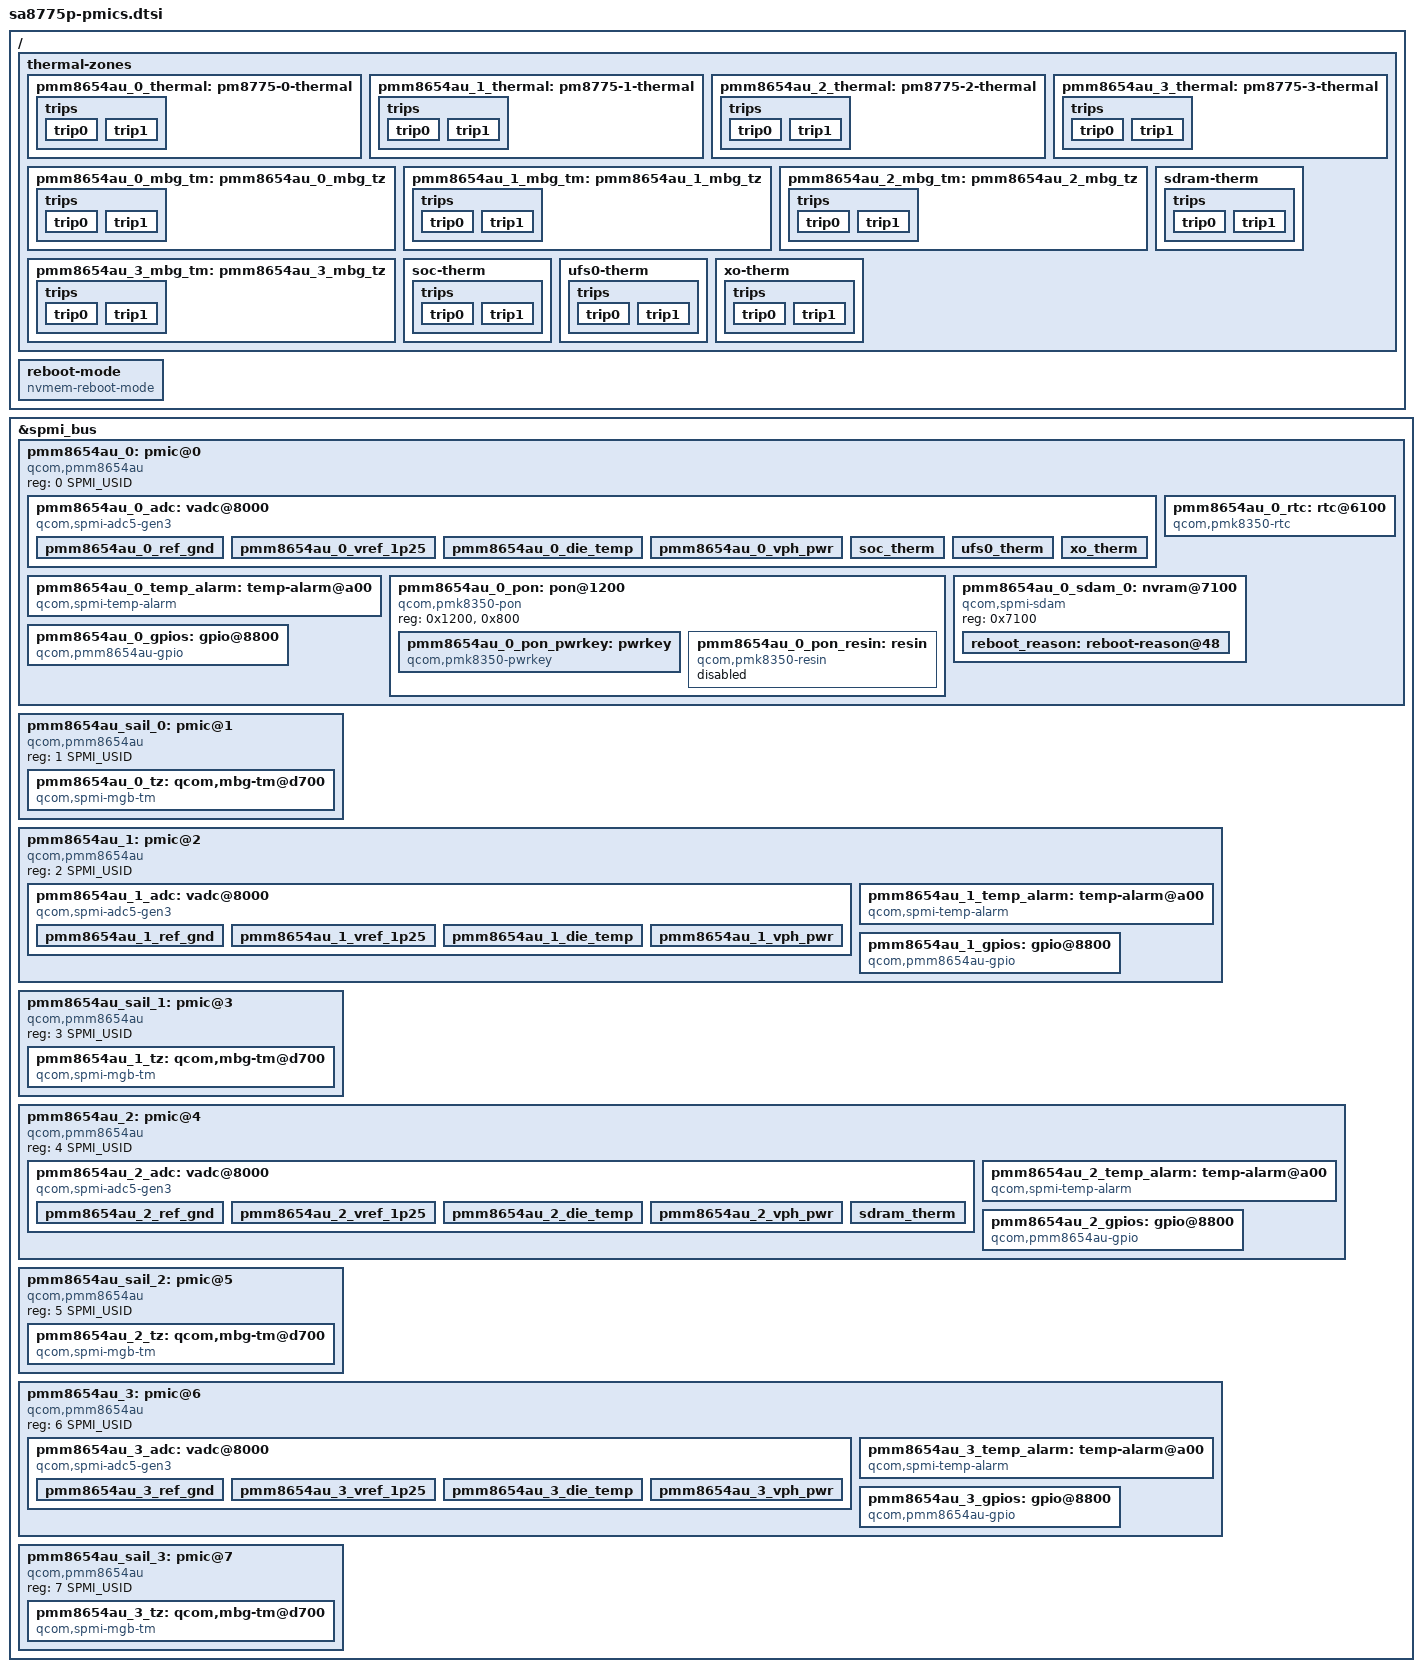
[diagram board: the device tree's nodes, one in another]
// SPDX-License-Identifier: BSD-3-Clause
/*
 * Copyright (c) 2023, Linaro Limited
 * Copyright (c) 2024, Qualcomm Innovation Center, Inc. All rights reserved.
 */

#include <dt-bindings/iio/qcom,spmi-adc5-gen3-pm8775.h>
#include <dt-bindings/input/input.h>
#include <dt-bindings/spmi/spmi.h>

/ {
	thermal-zones {
		pmm8654au_0_thermal: pm8775-0-thermal {
			polling-delay-passive = <100>;
			polling-delay = <0>;
			thermal-sensors = <&pmm8654au_0_temp_alarm>;

			trips {
				trip0 {
					temperature = <105000>;
					hysteresis = <0>;
					type = "passive";
				};

				trip1 {
					temperature = <125000>;
					hysteresis = <0>;
					type = "critical";
				};
			};
		};

		pmm8654au_1_thermal: pm8775-1-thermal {
			polling-delay-passive = <100>;
			polling-delay = <0>;
			thermal-sensors = <&pmm8654au_1_temp_alarm>;

			trips {
				trip0 {
					temperature = <105000>;
					hysteresis = <0>;
					type = "passive";
				};

				trip1 {
					temperature = <125000>;
					hysteresis = <0>;
					type = "critical";
				};
			};
		};

		pmm8654au_2_thermal: pm8775-2-thermal {
			polling-delay-passive = <100>;
			polling-delay = <0>;
			thermal-sensors = <&pmm8654au_2_temp_alarm>;

			trips {
				trip0 {
					temperature = <105000>;
					hysteresis = <0>;
					type = "passive";
				};

				trip1 {
					temperature = <125000>;
					hysteresis = <0>;
					type = "critical";
				};
			};
		};

		pmm8654au_3_thermal: pm8775-3-thermal {
			polling-delay-passive = <100>;
			polling-delay = <0>;
			thermal-sensors = <&pmm8654au_3_temp_alarm>;

			trips {
				trip0 {
					temperature = <105000>;
					hysteresis = <0>;
					type = "passive";
				};

				trip1 {
					temperature = <125000>;
					hysteresis = <0>;
					type = "critical";
				};
			};
		};

		pmm8654au_0_mbg_tm: pmm8654au_0_mbg_tz {
			polling-delay-passive = <100>;
			polling-delay = <0>;
			thermal-sensors = <&pmm8654au_0_tz>;

			trips {
				trip0 {
					temperature = <115000>;
					hysteresis = <5000>;
					type = "passive";
				};

				trip1 {
					temperature = <135000>;
					hysteresis = <5000>;
					type = "passive";
				};
			};
		};

		pmm8654au_1_mbg_tm: pmm8654au_1_mbg_tz {
			polling-delay-passive = <100>;
			polling-delay = <0>;
			thermal-sensors = <&pmm8654au_1_tz>;

			trips {
				trip0 {
					temperature = <115000>;
					hysteresis = <5000>;
					type = "passive";
				};

				trip1 {
					temperature = <135000>;
					hysteresis = <5000>;
					type = "passive";
				};
			};
		};

		pmm8654au_2_mbg_tm: pmm8654au_2_mbg_tz {
			polling-delay-passive = <100>;
			polling-delay = <0>;
			thermal-sensors = <&pmm8654au_2_tz>;

			trips {
				trip0 {
					temperature = <115000>;
					hysteresis = <5000>;
					type = "passive";
				};

				trip1 {
					temperature = <135000>;
					hysteresis = <5000>;
					type = "passive";
				};
			};
		};

		pmm8654au_3_mbg_tm: pmm8654au_3_mbg_tz {
			polling-delay-passive = <100>;
			polling-delay = <0>;
			thermal-sensors = <&pmm8654au_3_tz>;

			trips {
				trip0 {
					temperature = <115000>;
					hysteresis = <5000>;
					type = "passive";
				};

				trip1 {
					temperature = <135000>;
					hysteresis = <5000>;
					type = "passive";
				};

			};
		};

		sdram-therm {
			polling-delay-passive = <0>;
			polling-delay = <0>;
			thermal-sensors = <&pmm8654au_2_adc PM8775_3_ADC5_GEN3_AMUX6_THM_100K_PU>;
			trips {
				trip0 {
					temperature = <125000>;
					hysteresis = <1000>;
					type = "passive";
				};

				trip1 {
					temperature = <125000>;
					hysteresis = <1000>;
					type = "passive";
				};
			};
		};

		soc-therm {
			polling-delay-passive = <0>;
			polling-delay = <0>;
			thermal-sensors = <&pmm8654au_0_adc PM8775_1_ADC5_GEN3_AMUX6_THM_100K_PU>;
			trips {
				trip0 {
					temperature = <125000>;
					hysteresis = <1000>;
					type = "passive";
				};

				trip1 {
					temperature = <125000>;
					hysteresis = <1000>;
					type = "passive";
				};
			};
		};

		ufs0-therm {
			polling-delay-passive = <0>;
			polling-delay = <0>;
			thermal-sensors = <&pmm8654au_0_adc PM8775_1_ADC5_GEN3_AMUX5_THM_100K_PU>;
			trips {
				trip0 {
					temperature = <125000>;
					hysteresis = <1000>;
					type = "passive";
				};

				trip1 {
					temperature = <125000>;
					hysteresis = <1000>;
					type = "passive";
				};
			};
		};

		xo-therm {
			polling-delay-passive = <0>;
			polling-delay = <0>;
			thermal-sensors = <&pmm8654au_0_adc PM8775_1_ADC5_GEN3_AMUX1_THM_100K_PU>;
			trips {
				trip0 {
					temperature = <125000>;
					hysteresis = <1000>;
					type = "passive";
				};

				trip1 {
					temperature = <125000>;
					hysteresis = <1000>;
					type = "passive";
				};
			};
		};
	};

	reboot-mode {
		compatible = "nvmem-reboot-mode";
		nvmem-cells = <&reboot_reason>;
		nvmem-cell-names = "reboot-mode";
		mode-recovery = <0x01>;
		mode-bootloader = <0x02>;
	};
};

&spmi_bus {
	pmm8654au_0: pmic@0 {
		compatible = "qcom,pmm8654au", "qcom,spmi-pmic";
		reg = <0 SPMI_USID>;
		#address-cells = <1>;
		#size-cells = <0>;

		pmm8654au_0_adc: vadc@8000 {
			compatible = "qcom,spmi-adc5-gen3";
			reg = <0x8000>;
			reg-names = "adc5-gen3-base";
			#address-cells = <1>;
			#size-cells = <0>;
			interrupts-extended = <&spmi_bus 0x0 0x80 0x1 IRQ_TYPE_EDGE_RISING>;
			interrupt-names = "adc-sdam0";
			#io-channel-cells = <1>;
			#thermal-sensor-cells = <1>;

			pmm8654au_0_ref_gnd {
				reg = <PM8775_1_ADC5_GEN3_OFFSET_REF>;
				label = "pm8775_1_ref_gnd";
				qcom,pre-scaling = <1 1>;
			};

			pmm8654au_0_vref_1p25 {
				reg = <PM8775_1_ADC5_GEN3_1P25VREF>;
				label = "pm8775_1_vref_1p25";
				qcom,pre-scaling = <1 1>;
			};

			pmm8654au_0_die_temp {
				reg = <PM8775_1_ADC5_GEN3_DIE_TEMP>;
				label = "pm8775_1_die_temp";
				qcom,pre-scaling = <1 1>;
			};

			pmm8654au_0_vph_pwr {
				reg = <PM8775_1_ADC5_GEN3_VPH_PWR>;
				label = "pm8775_1_vph_pwr";
				qcom,pre-scaling = <1 3>;
			};

			soc_therm {
				reg = <PM8775_1_ADC5_GEN3_AMUX6_THM_100K_PU>;
				label = "pmm8654au_0_soc_therm";
				qcom,ratiometric;
				qcom,hw-settle-time = <200>;
				qcom,adc-tm;
				qcom,pre-scaling = <1 1>;
			};

			ufs0_therm {
				reg = <PM8775_1_ADC5_GEN3_AMUX5_THM_100K_PU>;
				label = "pmm8654au_0_ufs0_therm";
				qcom,ratiometric;
				qcom,hw-settle-time = <200>;
				qcom,adc-tm;
				qcom,pre-scaling = <1 1>;
			};

			xo_therm {
				reg = <PM8775_1_ADC5_GEN3_AMUX1_THM_100K_PU>;
				label = "pmm8654au_0_xo_therm";
				qcom,ratiometric;
				qcom,hw-settle-time = <700>;
				qcom,adc-tm;
				qcom,pre-scaling = <1 1>;
			};
		};

		pmm8654au_0_temp_alarm: temp-alarm@a00 {
			compatible = "qcom,spmi-temp-alarm";
			reg = <0xa00>;
			interrupts-extended = <&spmi_bus 0x0 0xa 0x0 IRQ_TYPE_EDGE_BOTH>;
			io-channels = <&pmm8654au_0_adc PM8775_1_ADC5_GEN3_DIE_TEMP>;
			io-channel-names = "thermal";
			#thermal-sensor-cells = <0>;
		};

		pmm8654au_0_pon: pon@1200 {
			compatible = "qcom,pmk8350-pon";
			reg = <0x1200>, <0x800>;
			reg-names = "hlos", "pbs";

			pmm8654au_0_pon_pwrkey: pwrkey {
				compatible = "qcom,pmk8350-pwrkey";
				interrupts-extended = <&spmi_bus 0x0 0x12 0x7 IRQ_TYPE_EDGE_BOTH>;
				linux,code = <KEY_POWER>;
				debounce = <15625>;
			};

			pmm8654au_0_pon_resin: resin {
				compatible = "qcom,pmk8350-resin";
				interrupts-extended = <&spmi_bus 0x0 0x12 0x6 IRQ_TYPE_EDGE_BOTH>;
				debounce = <15625>;
				status = "disabled";
			};
		};

		pmm8654au_0_rtc: rtc@6100 {
			compatible = "qcom,pmk8350-rtc";
			reg = <0x6100>, <0x6200>;
			reg-names = "rtc", "alarm";
			interrupts = <0x0 0x62 0x1 IRQ_TYPE_EDGE_RISING>;
			allow-set-time;
		};

		pmm8654au_0_sdam_0: nvram@7100 {
			compatible = "qcom,spmi-sdam";
			reg = <0x7100>;
			#address-cells = <1>;
			#size-cells = <1>;
			ranges = <0 0x7100 0x100>;

			reboot_reason: reboot-reason@48 {
				reg = <0x48 0x1>;
				bits = <1 7>;
			};
		};

		pmm8654au_0_gpios: gpio@8800 {
			compatible = "qcom,pmm8654au-gpio", "qcom,spmi-gpio";
			reg = <0x8800>;
			gpio-controller;
			gpio-ranges = <&pmm8654au_0_gpios 0 0 12>;
			#gpio-cells = <2>;
			interrupt-controller;
			#interrupt-cells = <2>;
		};
	};

	pmm8654au_sail_0: pmic@1 {
		compatible = "qcom,pmm8654au", "qcom,spmi-pmic";
		reg = <1 SPMI_USID>;
		#address-cells = <1>;
		#size-cells = <0>;

		pmm8654au_0_tz: qcom,mbg-tm@d700 {
			compatible = "qcom,spmi-mgb-tm";
			reg = <0xd700>;
			io-channels = <&pmm8654au_0_adc PM8775_1_ADC5_GEN3_DIE_TEMP>;
			io-channel-names = "thermal";
			interrupts-extended = <&spmi_bus 0x1 0xd7 0x0 IRQ_TYPE_EDGE_RISING>;
			#thermal-sensor-cells = <0>;
		};
	};

	pmm8654au_1: pmic@2 {
		compatible = "qcom,pmm8654au", "qcom,spmi-pmic";
		reg = <2 SPMI_USID>;
		#address-cells = <1>;
		#size-cells = <0>;

		pmm8654au_1_adc: vadc@8000 {
			compatible = "qcom,spmi-adc5-gen3";
			reg = <0x8000>;
			reg-names = "adc5-gen3-base";
			#address-cells = <1>;
			#size-cells = <0>;
			interrupts-extended = <&spmi_bus 0x2 0x80 0x1 IRQ_TYPE_EDGE_RISING>;
			interrupt-names = "adc-sdam0";
			#io-channel-cells = <1>;
			#thermal-sensor-cells = <1>;

			pmm8654au_1_ref_gnd {
				reg = <PM8775_2_ADC5_GEN3_OFFSET_REF>;
				label = "pm8775_2_ref_gnd";
				qcom,pre-scaling = <1 1>;
			};

			pmm8654au_1_vref_1p25 {
				reg = <PM8775_2_ADC5_GEN3_1P25VREF>;
				label = "pm8775_2_vref_1p25";
				qcom,pre-scaling = <1 1>;
			};

			pmm8654au_1_die_temp {
				reg = <PM8775_2_ADC5_GEN3_DIE_TEMP>;
				label = "pm8775_2_die_temp";
				qcom,pre-scaling = <1 1>;
			};

			pmm8654au_1_vph_pwr {
				reg = <PM8775_2_ADC5_GEN3_VPH_PWR>;
				label = "pm8775_2_vph_pwr";
				qcom,pre-scaling = <1 3>;
			};
		};

		pmm8654au_1_temp_alarm: temp-alarm@a00 {
			compatible = "qcom,spmi-temp-alarm";
			reg = <0xa00>;
			interrupts-extended = <&spmi_bus 0x2 0xa 0x0 IRQ_TYPE_EDGE_BOTH>;
			io-channels = <&pmm8654au_1_adc PM8775_2_ADC5_GEN3_DIE_TEMP>;
			io-channel-names = "thermal";
			#thermal-sensor-cells = <0>;
		};

		pmm8654au_1_gpios: gpio@8800 {
			compatible = "qcom,pmm8654au-gpio", "qcom,spmi-gpio";
			reg = <0x8800>;
			gpio-controller;
			gpio-ranges = <&pmm8654au_1_gpios 0 0 12>;
			#gpio-cells = <2>;
			interrupt-controller;
			#interrupt-cells = <2>;
		};
	};

	pmm8654au_sail_1: pmic@3 {
		compatible = "qcom,pmm8654au", "qcom,spmi-pmic";
		reg = <3 SPMI_USID>;
		#address-cells = <1>;
		#size-cells = <0>;

		pmm8654au_1_tz: qcom,mbg-tm@d700 {
			compatible = "qcom,spmi-mgb-tm";
			reg = <0xd700>;
			io-channels = <&pmm8654au_1_adc PM8775_2_ADC5_GEN3_DIE_TEMP>;
			io-channel-names = "thermal";
			interrupts-extended = <&spmi_bus 0x3 0xd7 0x0 IRQ_TYPE_EDGE_RISING>;
			#thermal-sensor-cells = <0>;
		};
	};

	pmm8654au_2: pmic@4 {
		compatible = "qcom,pmm8654au", "qcom,spmi-pmic";
		reg = <4 SPMI_USID>;
		#address-cells = <1>;
		#size-cells = <0>;

		pmm8654au_2_adc: vadc@8000 {
			compatible = "qcom,spmi-adc5-gen3";
			reg = <0x8000>;
			reg-names = "adc5-gen3-base";
			#address-cells = <1>;
			#size-cells = <0>;
			interrupts-extended = <&spmi_bus 0x4 0x80 0x1 IRQ_TYPE_EDGE_RISING>;
			interrupt-names = "adc-sdam0";
			#io-channel-cells = <1>;
			#thermal-sensor-cells = <1>;

			pmm8654au_2_ref_gnd {
				reg = <PM8775_3_ADC5_GEN3_OFFSET_REF>;
				label = "pm8775_3_ref_gnd";
				qcom,pre-scaling = <1 1>;
			};

			pmm8654au_2_vref_1p25 {
				reg = <PM8775_3_ADC5_GEN3_1P25VREF>;
				label = "pm8775_3_vref_1p25";
				qcom,pre-scaling = <1 1>;
			};

			pmm8654au_2_die_temp {
				reg = <PM8775_3_ADC5_GEN3_DIE_TEMP>;
				label = "pm8775_3_die_temp";
				qcom,pre-scaling = <1 1>;
			};

			pmm8654au_2_vph_pwr {
				reg = <PM8775_3_ADC5_GEN3_VPH_PWR>;
				label = "pm8775_3_vph_pwr";
				qcom,pre-scaling = <1 3>;
			};

			sdram_therm {
				reg = <PM8775_3_ADC5_GEN3_AMUX6_THM_100K_PU>;
				label = "pmm8654au_2_sdram_therm1";
				qcom,ratiometric;
				qcom,hw-settle-time = <200>;
				qcom,adc-tm;
				qcom,pre-scaling = <1 1>;
			};
		};

		pmm8654au_2_temp_alarm: temp-alarm@a00 {
			compatible = "qcom,spmi-temp-alarm";
			reg = <0xa00>;
			interrupts-extended = <&spmi_bus 0x4 0xa 0x0 IRQ_TYPE_EDGE_BOTH>;
			io-channels = <&pmm8654au_2_adc PM8775_3_ADC5_GEN3_DIE_TEMP>;
			io-channel-names = "thermal";
			#thermal-sensor-cells = <0>;
		};

		pmm8654au_2_gpios: gpio@8800 {
			compatible = "qcom,pmm8654au-gpio", "qcom,spmi-gpio";
			reg = <0x8800>;
			gpio-controller;
			gpio-ranges = <&pmm8654au_2_gpios 0 0 12>;
			#gpio-cells = <2>;
			interrupt-controller;
			#interrupt-cells = <2>;
		};
	};

	pmm8654au_sail_2: pmic@5 {
		compatible = "qcom,pmm8654au", "qcom,spmi-pmic";
		reg = <5 SPMI_USID>;
		#address-cells = <1>;
		#size-cells = <0>;

		pmm8654au_2_tz: qcom,mbg-tm@d700 {
			compatible = "qcom,spmi-mgb-tm";
			reg = <0xd700>;
			io-channels = <&pmm8654au_2_adc PM8775_3_ADC5_GEN3_DIE_TEMP>;
			io-channel-names = "thermal";
			interrupts-extended = <&spmi_bus 0x5 0xd7 0x0 IRQ_TYPE_EDGE_RISING>;
			#thermal-sensor-cells = <0>;
		};
	};

	pmm8654au_3: pmic@6 {
		compatible = "qcom,pmm8654au", "qcom,spmi-pmic";
		reg = <6 SPMI_USID>;
		#address-cells = <1>;
		#size-cells = <0>;

		pmm8654au_3_adc: vadc@8000 {
			compatible = "qcom,spmi-adc5-gen3";
			reg = <0x8000>;
			reg-names = "adc5-gen3-base";
			#address-cells = <1>;
			#size-cells = <0>;
			interrupts-extended = <&spmi_bus 0x6 0x80 0x1 IRQ_TYPE_EDGE_RISING>;
			interrupt-names = "adc-sdam0";
			#io-channel-cells = <1>;
			#thermal-sensor-cells = <1>;

			pmm8654au_3_ref_gnd {
				reg = <PM8775_4_ADC5_GEN3_OFFSET_REF>;
				label = "pm8775_4_ref_gnd";
				qcom,pre-scaling = <1 1>;
			};

			pmm8654au_3_vref_1p25 {
				reg = <PM8775_4_ADC5_GEN3_1P25VREF>;
				label = "pm8775_4_vref_1p25";
				qcom,pre-scaling = <1 1>;
			};

			pmm8654au_3_die_temp {
				reg = <PM8775_4_ADC5_GEN3_DIE_TEMP>;
				label = "pm8775_4_die_temp";
				qcom,pre-scaling = <1 1>;
			};

			pmm8654au_3_vph_pwr {
				reg = <PM8775_4_ADC5_GEN3_VPH_PWR>;
				label = "pm8775_4_vph_pwr";
				qcom,pre-scaling = <1 3>;
			};
		};

		pmm8654au_3_temp_alarm: temp-alarm@a00 {
			compatible = "qcom,spmi-temp-alarm";
			reg = <0xa00>;
			interrupts-extended = <&spmi_bus 0x6 0xa 0x0 IRQ_TYPE_EDGE_BOTH>;
			io-channels = <&pmm8654au_3_adc PM8775_4_ADC5_GEN3_DIE_TEMP>;
			io-channel-names = "thermal";
			#thermal-sensor-cells = <0>;
		};

		pmm8654au_3_gpios: gpio@8800 {
			compatible = "qcom,pmm8654au-gpio", "qcom,spmi-gpio";
			reg = <0x8800>;
			gpio-controller;
			gpio-ranges = <&pmm8654au_3_gpios 0 0 12>;
			#gpio-cells = <2>;
			interrupt-controller;
			#interrupt-cells = <2>;
		};
	};

	pmm8654au_sail_3: pmic@7 {
		compatible = "qcom,pmm8654au", "qcom,spmi-pmic";
		reg = <7 SPMI_USID>;
		#address-cells = <1>;
		#size-cells = <0>;

		pmm8654au_3_tz: qcom,mbg-tm@d700 {
			compatible = "qcom,spmi-mgb-tm";
			reg = <0xd700>;
			io-channels = <&pmm8654au_3_adc PM8775_4_ADC5_GEN3_DIE_TEMP>;
			io-channel-names = "thermal";
			interrupts-extended = <&spmi_bus 0x7 0xd7 0x0 IRQ_TYPE_EDGE_RISING>;
			#thermal-sensor-cells = <0>;
		};
	};
};
